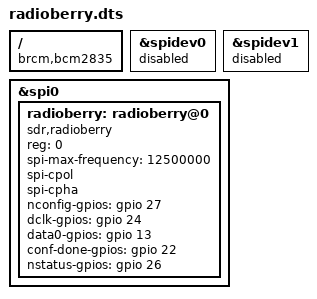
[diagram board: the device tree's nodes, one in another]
// SPDX-License-Identifier: GPL-2.0-or-later
/*
 * RadioBerry 2.x on the Raspberry Pi 4 and 5. Installed as radioberry.dtbo
 * and enabled with "dtoverlay=radioberry" in config.txt.
 *
 * The control interface is spi0 chip select 0 in SPI mode 3. The FPGA's
 * passive serial configuration lines are GPIOs handed to the driver. The
 * stream pins are not listed: on a Pi 5 the driver hands GPIO 4, 5, 6, 12,
 * 18 to 21 and 25 to the RP1 PIO, on a Pi 4 it puts GPIO 18 to 21 in their
 * PCM function itself.
 *
 * Only labels both boards' device trees define are used: spi0, spidev0,
 * spidev1 and gpio (the RP1 GPIO block on a Pi 5, the BCM2711 one on a
 * Pi 4). The Pi 5's RP1 PIO is enabled in its base tree.
 *
 * Parameter: spi_speed=<Hz> (default 12.5 MHz; the gateware's timing
 * constraints allow up to 15.625 MHz).
 */
/dts-v1/;
/plugin/;

/ {
	compatible = "brcm,bcm2835";

	fragment@0 {
		target = <&spidev0>;
		__overlay__ {
			status = "disabled";
		};
	};

	fragment@1 {
		target = <&spidev1>;
		__overlay__ {
			status = "disabled";
		};
	};

	fragment@2 {
		target = <&spi0>;
		__overlay__ {
			status = "okay";
			#address-cells = <1>;
			#size-cells = <0>;

			radioberry: radioberry@0 {
				compatible = "sdr,radioberry";
				reg = <0>;
				spi-max-frequency = <12500000>;
				spi-cpol;
				spi-cpha;
				nconfig-gpios = <&gpio 27 0>;
				dclk-gpios = <&gpio 24 0>;
				data0-gpios = <&gpio 13 0>;
				conf-done-gpios = <&gpio 22 0>;
				nstatus-gpios = <&gpio 26 0>;
				status = "okay";
			};
		};
	};

	__overrides__ {
		spi_speed = <&radioberry>, "spi-max-frequency:0";
	};
};
